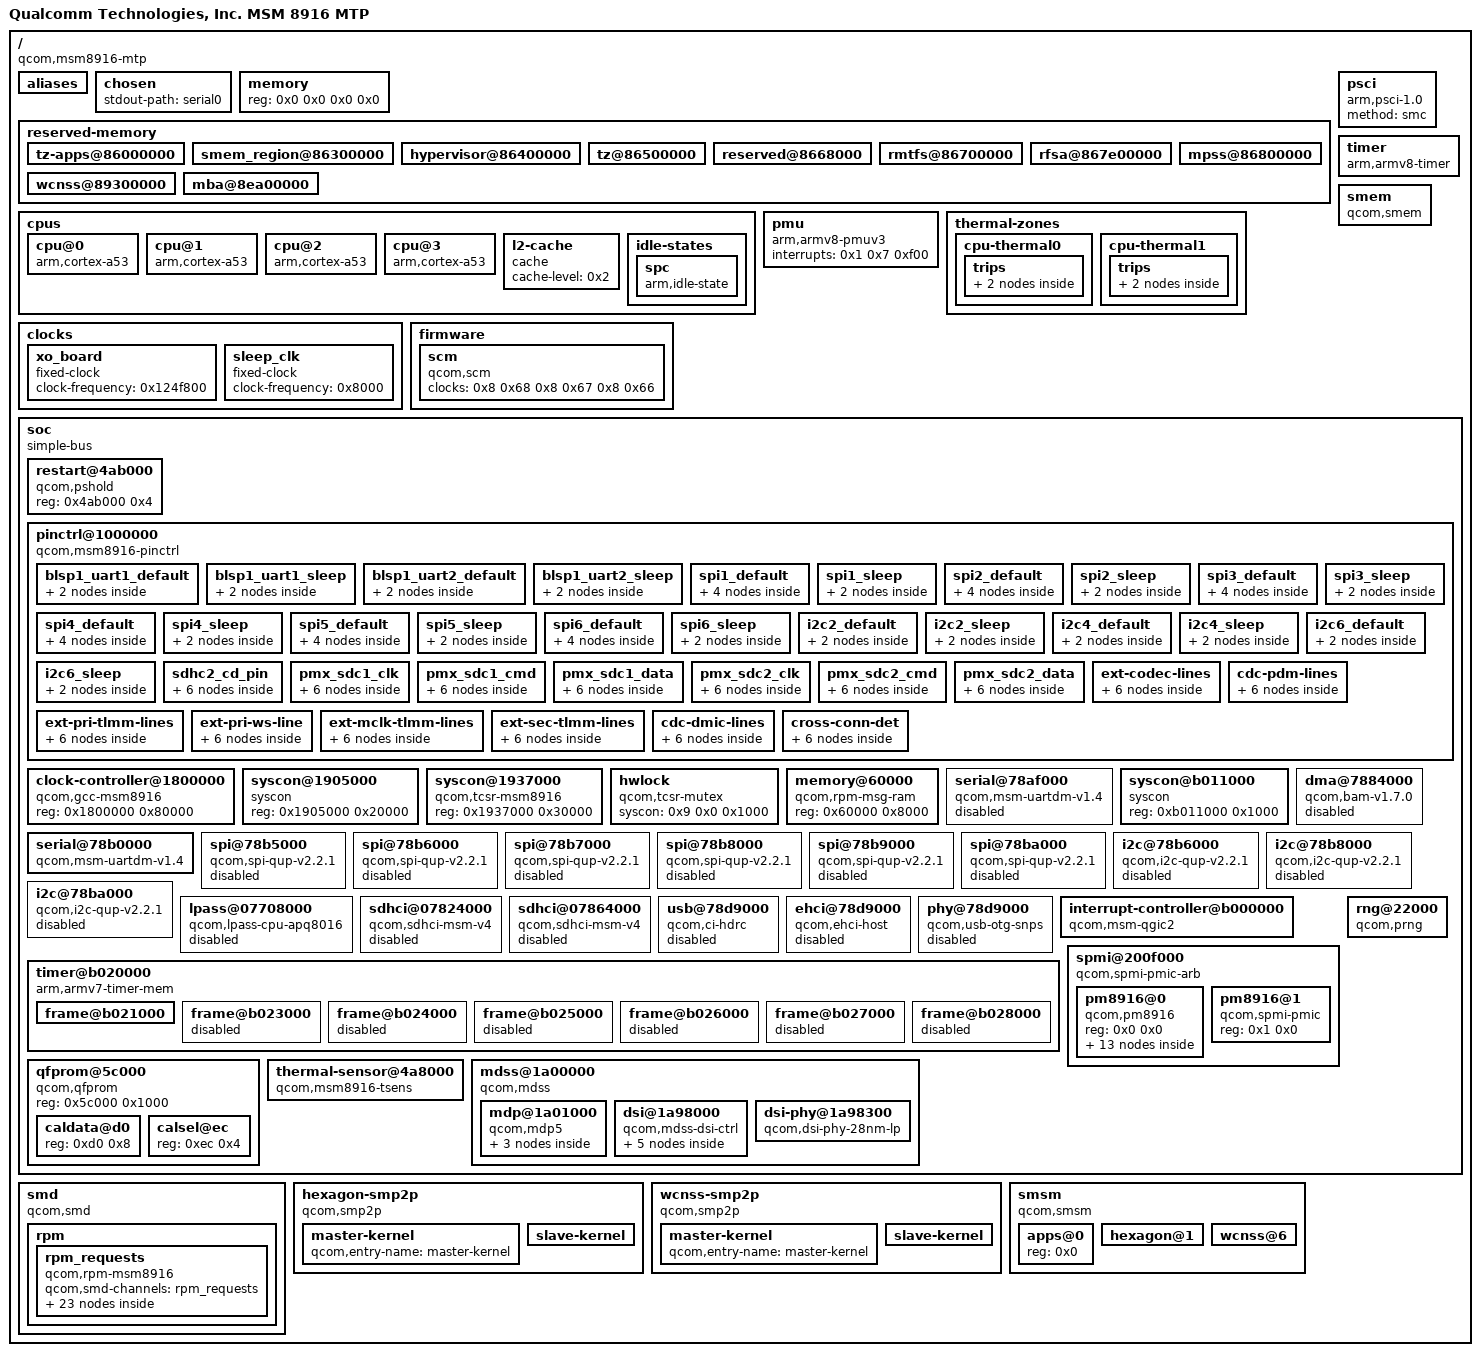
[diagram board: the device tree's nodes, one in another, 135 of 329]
/dts-v1/;

/ {
	model = "Qualcomm Technologies, Inc. MSM 8916 MTP";
	compatible = "qcom,msm8916-mtp", "qcom,msm8916-mtp/1", "qcom,msm8916", "qcom,mtp";
	interrupt-parent = <0x1>;
	#address-cells = <0x2>;
	#size-cells = <0x2>;

	aliases {
		sdhc1 = "/soc/sdhci@07824000";
		sdhc2 = "/soc/sdhci@07864000";
		serial0 = "/soc/serial@78b0000";
		usid0 = "/soc/spmi@200f000/pm8916@0";
	};

	chosen {
		stdout-path = "serial0";
	};

	memory {
		device_type = "memory";
		reg = <0x0 0x0 0x0 0x0>;
	};

	reserved-memory {
		#address-cells = <0x2>;
		#size-cells = <0x2>;
		ranges;

		tz-apps@86000000 {
			reg = <0x0 0x86000000 0x0 0x300000>;
			no-map;
		};

		smem_region@86300000 {
			reg = <0x0 0x86300000 0x0 0x100000>;
			no-map;
			linux,phandle = <0x5>;
			phandle = <0x5>;
		};

		hypervisor@86400000 {
			reg = <0x0 0x86400000 0x0 0x100000>;
			no-map;
		};

		tz@86500000 {
			reg = <0x0 0x86500000 0x0 0x180000>;
			no-map;
		};

		reserved@8668000 {
			reg = <0x0 0x86680000 0x0 0x80000>;
			no-map;
		};

		rmtfs@86700000 {
			reg = <0x0 0x86700000 0x0 0xe0000>;
			no-map;
		};

		rfsa@867e00000 {
			reg = <0x0 0x867e0000 0x0 0x20000>;
			no-map;
		};

		mpss@86800000 {
			reg = <0x0 0x86800000 0x0 0x2b00000>;
			no-map;
		};

		wcnss@89300000 {
			reg = <0x0 0x89300000 0x0 0x600000>;
			no-map;
		};

		mba@8ea00000 {
			no-map;
			reg = <0x0 0x8ea00000 0x0 0x100000>;
			linux,phandle = <0x28>;
			phandle = <0x28>;
		};
	};

	cpus {
		#address-cells = <0x1>;
		#size-cells = <0x0>;

		cpu@0 {
			device_type = "cpu";
			compatible = "arm,cortex-a53", "arm,armv8";
			reg = <0x0>;
			next-level-cache = <0x2>;
			enable-method = "psci";
			cpu-idle-states = <0x3>;
			linux,phandle = <0x29>;
			phandle = <0x29>;
		};

		cpu@1 {
			device_type = "cpu";
			compatible = "arm,cortex-a53", "arm,armv8";
			reg = <0x1>;
			next-level-cache = <0x2>;
			enable-method = "psci";
			cpu-idle-states = <0x3>;
			linux,phandle = <0x2a>;
			phandle = <0x2a>;
		};

		cpu@2 {
			device_type = "cpu";
			compatible = "arm,cortex-a53", "arm,armv8";
			reg = <0x2>;
			next-level-cache = <0x2>;
			enable-method = "psci";
			cpu-idle-states = <0x3>;
			linux,phandle = <0x2b>;
			phandle = <0x2b>;
		};

		cpu@3 {
			device_type = "cpu";
			compatible = "arm,cortex-a53", "arm,armv8";
			reg = <0x3>;
			next-level-cache = <0x2>;
			enable-method = "psci";
			cpu-idle-states = <0x3>;
			linux,phandle = <0x2c>;
			phandle = <0x2c>;
		};

		l2-cache {
			compatible = "cache";
			cache-level = <0x2>;
			linux,phandle = <0x2>;
			phandle = <0x2>;
		};

		idle-states {

			spc {
				compatible = "arm,idle-state";
				arm,psci-suspend-param = <0x40000002>;
				entry-latency-us = <0x82>;
				exit-latency-us = <0x96>;
				min-residency-us = <0x7d0>;
				local-timer-stop;
				linux,phandle = <0x3>;
				phandle = <0x3>;
			};
		};
	};

	psci {
		compatible = "arm,psci-1.0";
		method = "smc";
	};

	pmu {
		compatible = "arm,armv8-pmuv3";
		interrupts = <0x1 0x7 0xf00>;
	};

	thermal-zones {

		cpu-thermal0 {
			polling-delay-passive = <0xfa>;
			polling-delay = <0x3e8>;
			thermal-sensors = <0x4 0x4>;

			trips {

				trip0 {
					temperature = <0x124f8>;
					hysteresis = <0x7d0>;
					type = "passive";
					linux,phandle = <0x2d>;
					phandle = <0x2d>;
				};

				trip1 {
					temperature = <0x1adb0>;
					hysteresis = <0x7d0>;
					type = "critical";
					linux,phandle = <0x2e>;
					phandle = <0x2e>;
				};
			};
		};

		cpu-thermal1 {
			polling-delay-passive = <0xfa>;
			polling-delay = <0x3e8>;
			thermal-sensors = <0x4 0x3>;

			trips {

				trip0 {
					temperature = <0x124f8>;
					hysteresis = <0x7d0>;
					type = "passive";
					linux,phandle = <0x2f>;
					phandle = <0x2f>;
				};

				trip1 {
					temperature = <0x1adb0>;
					hysteresis = <0x7d0>;
					type = "critical";
					linux,phandle = <0x30>;
					phandle = <0x30>;
				};
			};
		};
	};

	timer {
		compatible = "arm,armv8-timer";
		interrupts = <0x1 0x2 0xf08 0x1 0x3 0xf08 0x1 0x4 0xf08 0x1 0x1 0xf08>;
	};

	clocks {

		xo_board {
			compatible = "fixed-clock";
			#clock-cells = <0x0>;
			clock-frequency = <0x124f800>;
			linux,phandle = <0x31>;
			phandle = <0x31>;
		};

		sleep_clk {
			compatible = "fixed-clock";
			#clock-cells = <0x0>;
			clock-frequency = <0x8000>;
			linux,phandle = <0x32>;
			phandle = <0x32>;
		};
	};

	smem {
		compatible = "qcom,smem";
		memory-region = <0x5>;
		qcom,rpm-msg-ram = <0x6>;
		hwlocks = <0x7 0x3>;
	};

	firmware {

		scm {
			compatible = "qcom,scm";
			clocks = <0x8 0x68 0x8 0x67 0x8 0x66>;
			clock-names = "core", "bus", "iface";
			#reset-cells = <0x1>;
			linux,phandle = <0x33>;
			phandle = <0x33>;
		};
	};

	soc {
		#address-cells = <0x1>;
		#size-cells = <0x1>;
		ranges = <0x0 0x0 0x0 0xffffffff>;
		compatible = "simple-bus";
		linux,phandle = <0x34>;
		phandle = <0x34>;

		restart@4ab000 {
			compatible = "qcom,pshold";
			reg = <0x4ab000 0x4>;
		};

		pinctrl@1000000 {
			compatible = "qcom,msm8916-pinctrl";
			reg = <0x1000000 0x300000>;
			interrupts = <0x0 0xd0 0x4>;
			gpio-controller;
			#gpio-cells = <0x2>;
			interrupt-controller;
			#interrupt-cells = <0x2>;
			linux,phandle = <0x35>;
			phandle = <0x35>;

			blsp1_uart1_default {
				linux,phandle = <0x36>;
				phandle = <0x36>;

				pinmux {
					function = "blsp_uart1";
					pins = "gpio0", "gpio1", "gpio2", "gpio3";
				};

				pinconf {
					pins = "gpio0", "gpio1", "gpio2", "gpio3";
					drive-strength = <0x10>;
					bias-disable;
				};
			};

			blsp1_uart1_sleep {
				linux,phandle = <0x37>;
				phandle = <0x37>;

				pinmux {
					function = "gpio";
					pins = "gpio0", "gpio1", "gpio2", "gpio3";
				};

				pinconf {
					pins = "gpio0", "gpio1", "gpio2", "gpio3";
					drive-strength = <0x2>;
					bias-pull-down;
				};
			};

			blsp1_uart2_default {
				linux,phandle = <0xb>;
				phandle = <0xb>;

				pinmux {
					function = "blsp_uart2";
					pins = "gpio4", "gpio5";
				};

				pinconf {
					pins = "gpio4", "gpio5";
					drive-strength = <0x10>;
					bias-disable;
				};
			};

			blsp1_uart2_sleep {
				linux,phandle = <0xc>;
				phandle = <0xc>;

				pinmux {
					function = "gpio";
					pins = "gpio4", "gpio5";
				};

				pinconf {
					pins = "gpio4", "gpio5";
					drive-strength = <0x2>;
					bias-pull-down;
				};
			};

			spi1_default {
				linux,phandle = <0xd>;
				phandle = <0xd>;

				pinmux {
					function = "blsp_spi1";
					pins = "gpio0", "gpio1", "gpio3";
				};

				pinmux_cs {
					function = "gpio";
					pins = "gpio2";
				};

				pinconf {
					pins = "gpio0", "gpio1", "gpio3";
					drive-strength = <0xc>;
					bias-disable;
				};

				pinconf_cs {
					pins = "gpio2";
					drive-strength = <0x10>;
					bias-disable;
					output-high;
				};
			};

			spi1_sleep {
				linux,phandle = <0xe>;
				phandle = <0xe>;

				pinmux {
					function = "gpio";
					pins = "gpio0", "gpio1", "gpio2", "gpio3";
				};

				pinconf {
					pins = "gpio0", "gpio1", "gpio2", "gpio3";
					drive-strength = <0x2>;
					bias-pull-down;
				};
			};

			spi2_default {
				linux,phandle = <0xf>;
				phandle = <0xf>;

				pinmux {
					function = "blsp_spi2";
					pins = "gpio4", "gpio5", "gpio7";
				};

				pinmux_cs {
					function = "gpio";
					pins = "gpio6";
				};

				pinconf {
					pins = "gpio4", "gpio5", "gpio7";
					drive-strength = <0xc>;
					bias-disable;
				};

				pinconf_cs {
					pins = "gpio6";
					drive-strength = <0x10>;
					bias-disable;
					output-high;
				};
			};

			spi2_sleep {
				linux,phandle = <0x10>;
				phandle = <0x10>;

				pinmux {
					function = "gpio";
					pins = "gpio4", "gpio5", "gpio6", "gpio7";
				};

				pinconf {
					pins = "gpio4", "gpio5", "gpio6", "gpio7";
					drive-strength = <0x2>;
					bias-pull-down;
				};
			};

			spi3_default {
				linux,phandle = <0x11>;
				phandle = <0x11>;

				pinmux {
					function = "blsp_spi3";
					pins = "gpio8", "gpio9", "gpio11";
				};

				pinmux_cs {
					function = "gpio";
					pins = "gpio10";
				};

				pinconf {
					pins = "gpio8", "gpio9", "gpio11";
					drive-strength = <0xc>;
					bias-disable;
				};

				pinconf_cs {
					pins = "gpio10";
					drive-strength = <0x10>;
					bias-disable;
					output-high;
				};
			};

			spi3_sleep {
				linux,phandle = <0x12>;
				phandle = <0x12>;

				pinmux {
					function = "gpio";
					pins = "gpio8", "gpio9", "gpio10", "gpio11";
				};

				pinconf {
					pins = "gpio8", "gpio9", "gpio10", "gpio11";
					drive-strength = <0x2>;
					bias-pull-down;
				};
			};

			spi4_default {
				linux,phandle = <0x13>;
				phandle = <0x13>;

				pinmux {
					function = "blsp_spi4";
					pins = "gpio12", "gpio13", "gpio15";
				};

				pinmux_cs {
					function = "gpio";
					pins = "gpio14";
				};

				pinconf {
					pins = "gpio12", "gpio13", "gpio15";
					drive-strength = <0xc>;
					bias-disable;
				};

				pinconf_cs {
					pins = "gpio14";
					drive-strength = <0x10>;
					bias-disable;
					output-high;
				};
			};

			spi4_sleep {
				linux,phandle = <0x14>;
				phandle = <0x14>;

				pinmux {
					function = "gpio";
					pins = "gpio12", "gpio13", "gpio14", "gpio15";
				};

				pinconf {
					pins = "gpio12", "gpio13", "gpio14", "gpio15";
					drive-strength = <0x2>;
					bias-pull-down;
				};
			};

			spi5_default {
				linux,phandle = <0x15>;
				phandle = <0x15>;

				pinmux {
					function = "blsp_spi5";
					pins = "gpio16", "gpio17", "gpio19";
				};

				pinmux_cs {
					function = "gpio";
					pins = "gpio18";
				};

				pinconf {
					pins = "gpio16", "gpio17", "gpio19";
					drive-strength = <0xc>;
					bias-disable;
				};

				pinconf_cs {
					pins = "gpio18";
					drive-strength = <0x10>;
					bias-disable;
					output-high;
				};
			};

			spi5_sleep {
				linux,phandle = <0x16>;
				phandle = <0x16>;

				pinmux {
					function = "gpio";
					pins = "gpio16", "gpio17", "gpio18", "gpio19";
				};

				pinconf {
					pins = "gpio16", "gpio17", "gpio18", "gpio19";
					drive-strength = <0x2>;
					bias-pull-down;
				};
			};

			spi6_default {
				linux,phandle = <0x17>;
				phandle = <0x17>;

				pinmux {
					function = "blsp_spi6";
					pins = "gpio20", "gpio21", "gpio23";
				};

				pinmux_cs {
					function = "gpio";
					pins = "gpio22";
				};

				pinconf {
					pins = "gpio20", "gpio21", "gpio23";
					drive-strength = <0xc>;
					bias-disable;
				};

				pinconf_cs {
					pins = "gpio22";
					drive-strength = <0x10>;
					bias-disable;
					output-high;
				};
			};

			spi6_sleep {
				linux,phandle = <0x18>;
				phandle = <0x18>;

				pinmux {
					function = "gpio";
					pins = "gpio20", "gpio21", "gpio22", "gpio23";
				};

				pinconf {
					pins = "gpio20", "gpio21", "gpio22", "gpio23";
					drive-strength = <0x2>;
					bias-pull-down;
				};
			};

			i2c2_default {
				linux,phandle = <0x19>;
				phandle = <0x19>;

				pinmux {
					function = "blsp_i2c2";
					pins = "gpio6", "gpio7";
				};

				pinconf {
					pins = "gpio6", "gpio7";
					drive-strength = <0x10>;
					bias-disable = <0x0>;
				};
			};

			i2c2_sleep {
				linux,phandle = <0x1a>;
				phandle = <0x1a>;

				pinmux {
					function = "gpio";
					pins = "gpio6", "gpio7";
				};

				pinconf {
					pins = "gpio6", "gpio7";
					drive-strength = <0x2>;
					bias-disable = <0x0>;
				};
			};

			i2c4_default {
				linux,phandle = <0x1b>;
				phandle = <0x1b>;

				pinmux {
					function = "blsp_i2c4";
					pins = "gpio14", "gpio15";
				};

				pinconf {
					pins = "gpio14", "gpio15";
					drive-strength = <0x10>;
					bias-disable = <0x0>;
				};
			};

			i2c4_sleep {
				linux,phandle = <0x1c>;
				phandle = <0x1c>;

				pinmux {
					function = "gpio";
					pins = "gpio14", "gpio15";
				};

				pinconf {
					pins = "gpio14", "gpio15";
					drive-strength = <0x2>;
					bias-disable = <0x0>;
				};
			};

			i2c6_default {
				linux,phandle = <0x1d>;
				phandle = <0x1d>;

				pinmux {
					function = "blsp_i2c6";
					pins = "gpio22", "gpio23";
				};

				pinconf {
					pins = "gpio22", "gpio23";
					drive-strength = <0x10>;
					bias-disable = <0x0>;
				};
			};

			i2c6_sleep {
				linux,phandle = <0x1e>;
				phandle = <0x1e>;

				pinmux {
					function = "gpio";
					pins = "gpio22", "gpio23";
				};

				pinconf {
					pins = "gpio22", "gpio23";
					drive-strength = <0x2>;
					bias-disable = <0x0>;
				};
			};

			sdhc2_cd_pin {

				cd_on {
					linux,phandle = <0x38>;
					phandle = <0x38>;

					pinmux {
						function = "gpio";
						pins = "gpio38";
					};

					pinconf {
						pins = "gpio38";
						drive-strength = <0x2>;
						bias-pull-up;
					};
				};

				cd_off {
					linux,phandle = <0x39>;
					phandle = <0x39>;

					pinmux {
						function = "gpio";
						pins = "gpio38";
					};

					pinconf {
						pins = "gpio38";
						drive-strength = <0x2>;
						bias-disable;
					};
				};
			};

			pmx_sdc1_clk {

				clk_on {
					linux,phandle = <0x3a>;
					phandle = <0x3a>;

					pinmux {
						pins = "sdc1_clk";
					};

					pinconf {
						pins = "sdc1_clk";
						bias-disable;
						drive-strength = <0x10>;
					};
				};

				clk_off {
					linux,phandle = <0x3b>;
					phandle = <0x3b>;

					pinmux {
						pins = "sdc1_clk";
					};

					pinconf {
						pins = "sdc1_clk";
						bias-disable;
						drive-strength = <0x2>;
					};
				};
			};

			pmx_sdc1_cmd {

				cmd_on {
					linux,phandle = <0x3c>;
					phandle = <0x3c>;

					pinmux {
						pins = "sdc1_cmd";
					};

					pinconf {
						pins = "sdc1_cmd";
						bias-pull-up;
						drive-strength = <0xa>;
					};
				};

				cmd_off {
					linux,phandle = <0x3d>;
					phandle = <0x3d>;

					pinmux {
						pins = "sdc1_cmd";
					};

					pinconf {
						pins = "sdc1_cmd";
						bias-pull-up;
						drive-strength = <0x2>;
					};
				};
			};

			pmx_sdc1_data {

				data_on {
					linux,phandle = <0x3e>;
					phandle = <0x3e>;

					pinmux {
						pins = "sdc1_data";
					};

					pinconf {
						pins = "sdc1_data";
						bias-pull-up;
						drive-strength = <0xa>;
					};
				};

				data_off {
					linux,phandle = <0x3f>;
					phandle = <0x3f>;

					pinmux {
						pins = "sdc1_data";
					};

					pinconf {
						pins = "sdc1_data";
						bias-pull-up;
						drive-strength = <0x2>;
					};
				};
			};

			pmx_sdc2_clk {

				clk_on {
					linux,phandle = <0x40>;
					phandle = <0x40>;

					pinmux {
						pins = "sdc2_clk";
					};

					pinconf {
						pins = "sdc2_clk";
						bias-disable;
						drive-strength = <0x10>;
					};
				};

				clk_off {
					linux,phandle = <0x41>;
					phandle = <0x41>;

					pinmux {
						pins = "sdc2_clk";
					};

					pinconf {
						pins = "sdc2_clk";
						bias-disable;
						drive-strength = <0x2>;
					};
				};
			};

			pmx_sdc2_cmd {

				cmd_on {
					linux,phandle = <0x42>;
					phandle = <0x42>;

					pinmux {
						pins = "sdc2_cmd";
					};

					pinconf {
						pins = "sdc2_cmd";
						bias-pull-up;
						drive-strength = <0xa>;
					};
				};

				cmd_off {
					linux,phandle = <0x43>;
					phandle = <0x43>;

					pinmux {
						pins = "sdc2_cmd";
					};

					pinconf {
						pins = "sdc2_cmd";
						bias-pull-up;
						drive-strength = <0x2>;
					};
				};
			};

			pmx_sdc2_data {

				data_on {
					linux,phandle = <0x44>;
					phandle = <0x44>;

					pinmux {
						pins = "sdc2_data";
					};

					pinconf {
						pins = "sdc2_data";
						bias-pull-up;
						drive-strength = <0xa>;
					};
				};

				data_off {
					linux,phandle = <0x45>;
					phandle = <0x45>;

					pinmux {
						pins = "sdc2_data";
					};

					pinconf {
						pins = "sdc2_data";
						bias-pull-up;
						drive-strength = <0x2>;
					};
				};
			};

			ext-codec-lines {

				lines_on {
					linux,phandle = <0x46>;
					phandle = <0x46>;

					pinmux {
						function = "gpio";
						pins = "gpio67";
					};

					pinconf {
						pins = "gpio67";
						drive-strength = <0x8>;
						bias-disable;
						output-high;
					};
				};

				lines_off {
					linux,phandle = <0x47>;
					phandle = <0x47>;

					pinmux {
						function = "gpio";
						pins = "gpio67";
					};

					pinconf {
						pins = "gpio67";
						drive-strength = <0x2>;
						bias-disable;
					};
				};
			};

			cdc-pdm-lines {

				pdm_lines_on {
					linux,phandle = <0x48>;
					phandle = <0x48>;

					pinmux {
						function = "cdc_pdm0";
						pins = "gpio63", "gpio64", "gpio65", "gpio66", "gpio67", "gpio68";
					};

					pinconf {
						pins = "gpio63", "gpio64", "gpio65", "gpio66", "gpio67", "gpio68";
						drive-strength = <0x8>;
						bias-pull-none;
					};
				};

				pdm_lines_off {
					linux,phandle = <0x49>;
					phandle = <0x49>;

					pinmux {
						function = "cdc_pdm0";
						pins = "gpio63", "gpio64", "gpio65", "gpio66", "gpio67", "gpio68";
					};

					pinconf {
						pins = "gpio63", "gpio64", "gpio65", "gpio66", "gpio67", "gpio68";
						drive-strength = <0x2>;
						bias-disable;
					};
				};
			};

			ext-pri-tlmm-lines {

				ext_pa_on {
					linux,phandle = <0x4a>;
					phandle = <0x4a>;

					pinmux {
						function = "pri_mi2s";
						pins = "gpio113", "gpio114", "gpio115", "gpio116";
					};

					pinconf {
						pins = "gpio113", "gpio114", "gpio115", "gpio116";
						drive-strength = <0x8>;
						bias-pull-none;
					};
				};

				ext_pa_off {
					linux,phandle = <0x4b>;
					phandle = <0x4b>;

					pinmux {
						function = "pri_mi2s";
						pins = "gpio113", "gpio114", "gpio115", "gpio116";
					};

					pinconf {
						pins = "gpio113", "gpio114", "gpio115", "gpio116";
						drive-strength = <0x2>;
						bias-disable;
					};
				};
			};

			ext-pri-ws-line {

				ext_pa_on {
					linux,phandle = <0x4c>;
					phandle = <0x4c>;

					pinmux {
						function = "pri_mi2s_ws";
						pins = "gpio110";
					};

					pinconf {
						pins = "gpio110";
						drive-strength = <0x8>;
						bias-pull-none;
					};
				};

				ext_pa_off {
					linux,phandle = <0x4d>;
					phandle = <0x4d>;

					pinmux {
						function = "pri_mi2s_ws";
						pins = "gpio110";
					};

					pinconf {
						pins = "gpio110";
						drive-strength = <0x2>;
						bias-disable;
					};
				};
			};

			ext-mclk-tlmm-lines {

				mclk_lines_on {
					linux,phandle = <0x4e>;
					phandle = <0x4e>;

					pinmux {
						function = "pri_mi2s";
						pins = "gpio116";
					};

					pinconf {
						pins = "gpio116";
						drive-strength = <0x8>;
						bias-pull-none;
					};
				};

				mclk_lines_off {
					linux,phandle = <0x4f>;
					phandle = <0x4f>;

					pinmux {
						function = "pri_mi2s";
						pins = "gpio116";
					};

					pinconf {
						pins = "gpio116";
						drive-strength = <0x2>;
						bias-disable;
					};
				};
			};

			ext-sec-tlmm-lines {

				tlmm_lines_on {
					linux,phandle = <0x50>;
					phandle = <0x50>;

					pinmux {
						function = "sec_mi2s";
						pins = "gpio112", "gpio117", "gpio118", "gpio119";
					};

					pinconf {
						pins = "gpio112", "gpio117", "gpio118", "gpio119";
						drive-strength = <0x8>;
						bias-pull-none;
					};
				};

				tlmm_lines_off {
					linux,phandle = <0x51>;
					phandle = <0x51>;

					pinmux {
						function = "sec_mi2s";
						pins = "gpio112", "gpio117", "gpio118", "gpio119";
					};

					pinconf {
						pins = "gpio112", "gpio117", "gpio118", "gpio119";
						drive-strength = <0x2>;
						bias-disable;
					};
				};
			};

			cdc-dmic-lines {

				dmic_lines_on {
					linux,phandle = <0x52>;
					phandle = <0x52>;

					pinmux_dmic0_clk {
						function = "dmic0_clk";
						pins = "gpio0";
					};

					pinmux_dmic0_data {
						function = "dmic0_data";
						pins = "gpio1";
					};

					pinconf {
						pins = "gpio0", "gpio1";
						drive-strength = <0x8>;
					};
				};

				dmic_lines_off {
					linux,phandle = <0x53>;
					phandle = <0x53>;

					pinconf {
						pins = "gpio0", "gpio1";
						drive-strength = <0x2>;
						bias-disable;
					};
				};
			};

			cross-conn-det {

				lines_on {
					linux,phandle = <0x54>;
					phandle = <0x54>;

					pinmux {
						function = "gpio";
						pins = "gpio120";
					};

					pinconf {
						pins = "gpio120";
						drive-strength = <0x8>;
						output-low;
						bias-pull-down;
					};
				};

				lines_off {
					linux,phandle = <0x55>;
					phandle = <0x55>;

					pinmux {
						function = "gpio";
						pins = "gpio120";
					};

					pinconf {
						pins = "gpio120";
						drive-strength = <0x2>;
						bias-disable;
					};
				};
			};
		};

		clock-controller@1800000 {
			compatible = "qcom,gcc-msm8916";
			#clock-cells = <0x1>;
			#reset-cells = <0x1>;
			#power-domain-cells = <0x1>;
			reg = <0x1800000 0x80000>;
			linux,phandle = <0x8>;
			phandle = <0x8>;
		};

		syscon@1905000 {
			compatible = "syscon";
			reg = <0x1905000 0x20000>;
			linux,phandle = <0x9>;
			phandle = <0x9>;
		};

		syscon@1937000 {
			compatible = "qcom,tcsr-msm8916", "syscon";
			reg = <0x1937000 0x30000>;
			linux,phandle = <0x56>;
			phandle = <0x56>;
		};

		hwlock {
			compatible = "qcom,tcsr-mutex";
			syscon = <0x9 0x0 0x1000>;
			#hwlock-cells = <0x1>;
			linux,phandle = <0x7>;
			phandle = <0x7>;
		};

		memory@60000 {
			compatible = "qcom,rpm-msg-ram";
			reg = <0x60000 0x8000>;
			linux,phandle = <0x6>;
			phandle = <0x6>;
		};

		serial@78af000 {
			compatible = "qcom,msm-uartdm-v1.4", "qcom,msm-uartdm";
			reg = <0x78af000 0x200>;
			interrupts = <0x0 0x6b 0x4>;
			clocks = <0x8 0x44 0x8 0x36>;
			clock-names = "core", "iface";
			dmas = <0xa 0x1 0xa 0x0>;
			dma-names = "rx", "tx";
			status = "disabled";
			linux,phandle = <0x57>;
			phandle = <0x57>;
		};

		syscon@b011000 {
			compatible = "syscon";
			reg = <0xb011000 0x1000>;
			linux,phandle = <0x27>;
			phandle = <0x27>;
		};

		serial@78b0000 {
			compatible = "qcom,msm-uartdm-v1.4", "qcom,msm-uartdm";
			reg = <0x78b0000 0x200>;
			interrupts = <0x0 0x6c 0x4>;
			clocks = <0x8 0x45 0x8 0x36>;
			clock-names = "core", "iface";
			dmas = <0xa 0x3 0xa 0x2>;
			dma-names = "rx", "tx";
			status = "okay";
			pinctrl-names = "default", "sleep";
			pinctrl-0 = <0xb>;
			pinctrl-1 = <0xc>;
			linux,phandle = <0x58>;
			phandle = <0x58>;
		};

		dma@7884000 {
			compatible = "qcom,bam-v1.7.0";
			reg = <0x7884000 0x23000>;
			interrupts = <0x0 0xee 0x4>;
			clocks = <0x8 0x36>;
			clock-names = "bam_clk";
			#dma-cells = <0x1>;
			qcom,ee = <0x0>;
			status = "disabled";
			linux,phandle = <0xa>;
			phandle = <0xa>;
		};

		spi@78b5000 {
			compatible = "qcom,spi-qup-v2.2.1";
			reg = <0x78b5000 0x600>;
			interrupts = <0x0 0x5f 0x4>;
			clocks = <0x8 0x39 0x8 0x36>;
			clock-names = "core", "iface";
			dmas = <0xa 0x5 0xa 0x4>;
			dma-names = "rx", "tx";
			pinctrl-names = "default", "sleep";
			pinctrl-0 = <0xd>;
			pinctrl-1 = <0xe>;
			#address-cells = <0x1>;
			#size-cells = <0x0>;
			status = "disabled";
			linux,phandle = <0x59>;
			phandle = <0x59>;
		};

		spi@78b6000 {
			compatible = "qcom,spi-qup-v2.2.1";
			reg = <0x78b6000 0x600>;
			interrupts = <0x0 0x60 0x4>;
			clocks = <0x8 0x3b 0x8 0x36>;
			clock-names = "core", "iface";
			dmas = <0xa 0x7 0xa 0x6>;
			dma-names = "rx", "tx";
			pinctrl-names = "default", "sleep";
			pinctrl-0 = <0xf>;
			pinctrl-1 = <0x10>;
			#address-cells = <0x1>;
			#size-cells = <0x0>;
			status = "disabled";
			linux,phandle = <0x5a>;
			phandle = <0x5a>;
		};

		spi@78b7000 {
			compatible = "qcom,spi-qup-v2.2.1";
			reg = <0x78b7000 0x600>;
			interrupts = <0x0 0x61 0x4>;
			clocks = <0x8 0x3d 0x8 0x36>;
			clock-names = "core", "iface";
			dmas = <0xa 0x9 0xa 0x8>;
			dma-names = "rx", "tx";
			pinctrl-names = "default", "sleep";
			pinctrl-0 = <0x11>;
			pinctrl-1 = <0x12>;
			#address-cells = <0x1>;
			#size-cells = <0x0>;
			status = "disabled";
			linux,phandle = <0x5b>;
			phandle = <0x5b>;
		};

		spi@78b8000 {
			compatible = "qcom,spi-qup-v2.2.1";
			reg = <0x78b8000 0x600>;
			interrupts = <0x0 0x62 0x4>;
			clocks = <0x8 0x3f 0x8 0x36>;
			clock-names = "core", "iface";
			dmas = <0xa 0xb 0xa 0xa>;
			dma-names = "rx", "tx";
			pinctrl-names = "default", "sleep";
			pinctrl-0 = <0x13>;
			pinctrl-1 = <0x14>;
			#address-cells = <0x1>;
			#size-cells = <0x0>;
			status = "disabled";
			linux,phandle = <0x5c>;
			phandle = <0x5c>;
		};

		spi@78b9000 {
			compatible = "qcom,spi-qup-v2.2.1";
			reg = <0x78b9000 0x600>;
			interrupts = <0x0 0x63 0x4>;
			clocks = <0x8 0x41 0x8 0x36>;
			clock-names = "core", "iface";
			dmas = <0xa 0xd 0xa 0xc>;
			dma-names = "rx", "tx";
			pinctrl-names = "default", "sleep";
			pinctrl-0 = <0x15>;
			pinctrl-1 = <0x16>;
			#address-cells = <0x1>;
			#size-cells = <0x0>;
			status = "disabled";
			linux,phandle = <0x5d>;
			phandle = <0x5d>;
		};

		spi@78ba000 {
			compatible = "qcom,spi-qup-v2.2.1";
			reg = <0x78ba000 0x600>;
			interrupts = <0x0 0x64 0x4>;
			clocks = <0x8 0x43 0x8 0x36>;
			clock-names = "core", "iface";
			dmas = <0xa 0xf 0xa 0xe>;
			dma-names = "rx", "tx";
			pinctrl-names = "default", "sleep";
			pinctrl-0 = <0x17>;
			pinctrl-1 = <0x18>;
			#address-cells = <0x1>;
			#size-cells = <0x0>;
			status = "disabled";
			linux,phandle = <0x5e>;
			phandle = <0x5e>;
		};

		i2c@78b6000 {
			compatible = "qcom,i2c-qup-v2.2.1";
			reg = <0x78b6000 0x1000>;
			interrupts = <0x0 0x60 0x0>;
			clocks = <0x8 0x36 0x8 0x3a>;
			clock-names = "iface", "core";
			pinctrl-names = "default", "sleep";
			pinctrl-0 = <0x19>;
			pinctrl-1 = <0x1a>;
			#address-cells = <0x1>;
			#size-cells = <0x0>;
			status = "disabled";
			linux,phandle = <0x5f>;
			phandle = <0x5f>;
		};

		i2c@78b8000 {
			compatible = "qcom,i2c-qup-v2.2.1";
			reg = <0x78b8000 0x1000>;
			interrupts = <0x0 0x62 0x0>;
			clocks = <0x8 0x36 0x8 0x3e>;
			clock-names = "iface", "core";
			pinctrl-names = "default", "sleep";
			pinctrl-0 = <0x1b>;
			pinctrl-1 = <0x1c>;
			#address-cells = <0x1>;
			#size-cells = <0x0>;
			status = "disabled";
			linux,phandle = <0x60>;
			phandle = <0x60>;
		};

		i2c@78ba000 {
			compatible = "qcom,i2c-qup-v2.2.1";
			reg = <0x78ba000 0x1000>;
			interrupts = <0x0 0x64 0x0>;
			clocks = <0x8 0x36 0x8 0x42>;
			clock-names = "iface", "core";
			pinctrl-names = "default", "sleep";
			pinctrl-0 = <0x1d>;
			pinctrl-1 = <0x1e>;
			#address-cells = <0x1>;
			#size-cells = <0x0>;
			status = "disabled";
			linux,phandle = <0x61>;
			phandle = <0x61>;
		};

		lpass@07708000 {
			status = "disabled";
			compatible = "qcom,lpass-cpu-apq8016";
			clocks = <0x8 0x9a 0x8 0x96 0x8 0x97 0x8 0x9c 0x8 0x9d 0x8 0x9d 0x8 0x9e>;
			clock-names = "ahbix-clk", "pcnoc-mport-clk", "pcnoc-sway-clk", "mi2s-bit-clk0", "mi2s-bit-clk1", "mi2s-bit-clk2", "mi2s-bit-clk3";
			#sound-dai-cells = <0x1>;
			interrupts = <0x0 0xa0 0x0>;
			interrupt-names = "lpass-irq-lpaif";
			reg = <0x7708000 0x10000>;
			reg-names = "lpass-lpaif";
			linux,phandle = <0x62>;
			phandle = <0x62>;
		};

		sdhci@07824000 {
			compatible = "qcom,sdhci-msm-v4";
			reg = <0x7824900 0x11c 0x7824000 0x800>;
			reg-names = "hc_mem", "core_mem";
			interrupts = <0x0 0x7b 0x0 0x0 0x8a 0x0>;
			interrupt-names = "hc_irq", "pwr_irq";
			clocks = <0x8 0x7b 0x8 0x7a>;
			clock-names = "core", "iface";
			bus-width = <0x8>;
			non-removable;
			status = "disabled";
			linux,phandle = <0x63>;
			phandle = <0x63>;
		};

		sdhci@07864000 {
			compatible = "qcom,sdhci-msm-v4";
			reg = <0x7864900 0x11c 0x7864000 0x800>;
			reg-names = "hc_mem", "core_mem";
			interrupts = <0x0 0x7d 0x0 0x0 0xdd 0x0>;
			interrupt-names = "hc_irq", "pwr_irq";
			clocks = <0x8 0x7d 0x8 0x7c>;
			clock-names = "core", "iface";
			bus-width = <0x4>;
			status = "disabled";
			linux,phandle = <0x64>;
			phandle = <0x64>;
		};

		usb@78d9000 {
			compatible = "qcom,ci-hdrc";
			reg = <0x78d9000 0x400>;
			dr_mode = "peripheral";
			interrupts = <0x0 0x86 0x4>;
			usb-phy = <0x1f>;
			status = "disabled";
			linux,phandle = <0x65>;
			phandle = <0x65>;
		};

		ehci@78d9000 {
			compatible = "qcom,ehci-host";
			reg = <0x78d9000 0x400>;
			interrupts = <0x0 0x86 0x4>;
			usb-phy = <0x1f>;
			status = "disabled";
			linux,phandle = <0x66>;
			phandle = <0x66>;
		};

		phy@78d9000 {
			compatible = "qcom,usb-otg-snps";
			reg = <0x78d9000 0x400>;
			interrupts = <0x0 0x86 0x4 0x0 0x8c 0x4>;
			qcom,vdd-levels = <0x7a120 0xf4240 0x142440>;
			qcom,phy-init-sequence = <0x44 0x6b 0x24 0x13>;
			dr_mode = "peripheral";
			qcom,otg-control = <0x2>;
			qcom,manual-pullup;
			clocks = <0x8 0x85 0x8 0x86 0x8 0x84>;
			clock-names = "iface", "core", "sleep";
			resets = <0x8 0x23 0x8 0x22>;
			reset-names = "phy", "link";
			status = "disabled";
			linux,phandle = <0x1f>;
			phandle = <0x1f>;
		};

		interrupt-controller@b000000 {
			compatible = "qcom,msm-qgic2";
			interrupt-controller;
			#interrupt-cells = <0x3>;
			reg = <0xb000000 0x1000 0xb002000 0x1000>;
			linux,phandle = <0x1>;
			phandle = <0x1>;
		};

		timer@b020000 {
			#address-cells = <0x1>;
			#size-cells = <0x1>;
			ranges;
			compatible = "arm,armv7-timer-mem";
			reg = <0xb020000 0x1000>;
			clock-frequency = <0x124f800>;

			frame@b021000 {
				frame-number = <0x0>;
				interrupts = <0x0 0x8 0x4 0x0 0x7 0x4>;
				reg = <0xb021000 0x1000 0xb022000 0x1000>;
			};

			frame@b023000 {
				frame-number = <0x1>;
				interrupts = <0x0 0x9 0x4>;
				reg = <0xb023000 0x1000>;
				status = "disabled";
			};

			frame@b024000 {
				frame-number = <0x2>;
				interrupts = <0x0 0xa 0x4>;
				reg = <0xb024000 0x1000>;
				status = "disabled";
			};

			frame@b025000 {
				frame-number = <0x3>;
				interrupts = <0x0 0xb 0x4>;
				reg = <0xb025000 0x1000>;
				status = "disabled";
			};

			frame@b026000 {
				frame-number = <0x4>;
				interrupts = <0x0 0xc 0x4>;
				reg = <0xb026000 0x1000>;
				status = "disabled";
			};

			frame@b027000 {
				frame-number = <0x5>;
				interrupts = <0x0 0xd 0x4>;
				reg = <0xb027000 0x1000>;
				status = "disabled";
			};

			frame@b028000 {
				frame-number = <0x6>;
				interrupts = <0x0 0xe 0x4>;
				reg = <0xb028000 0x1000>;
				status = "disabled";
			};
		};

		spmi@200f000 {
			compatible = "qcom,spmi-pmic-arb";
			reg = <0x200f000 0x1000 0x2400000 0x400000 0x2c00000 0x400000 0x3800000 0x200000 0x200a000 0x2100>;
			reg-names = "core", "chnls", "obsrvr", "intr", "cnfg";
			interrupt-names = "periph_irq";
			interrupts = <0x0 0xbe 0x4>;
			qcom,ee = <0x0>;
			qcom,channel = <0x0>;
			#address-cells = <0x2>;
			#size-cells = <0x0>;
			interrupt-controller;
			#interrupt-cells = <0x4>;
			linux,phandle = <0x67>;
			phandle = <0x67>;

			pm8916@0 {
				compatible = "qcom,pm8916", "qcom,spmi-pmic";
				reg = <0x0 0x0>;
				#address-cells = <0x1>;
				#size-cells = <0x0>;
				linux,phandle = <0x68>;
				phandle = <0x68>;

				rtc@6000 {
					compatible = "qcom,pm8941-rtc";
					reg = <0x6000>;
					reg-names = "rtc", "alarm";
					interrupts = <0x0 0x61 0x1 0x1>;
				};

				pwrkey@800 {
					compatible = "qcom,pm8941-pwrkey";
					reg = <0x800>;
					interrupts = <0x0 0x8 0x0 0x3>;
					debounce = <0x3d09>;
					bias-pull-up;
				};

				gpios@c000 {
					compatible = "qcom,pm8916-gpio";
					reg = <0xc000>;
					gpio-controller;
					#gpio-cells = <0x2>;
					interrupts = <0x0 0xc0 0x0 0x0 0x0 0xc1 0x0 0x0 0x0 0xc2 0x0 0x0 0x0 0xc3 0x0 0x0>;
					linux,phandle = <0x69>;
					phandle = <0x69>;
				};

				mpps@a000 {
					compatible = "qcom,pm8916-mpp";
					reg = <0xa000>;
					gpio-controller;
					#gpio-cells = <0x2>;
					interrupts = <0x0 0xa0 0x0 0x0 0x0 0xa1 0x0 0x0 0x0 0xa2 0x0 0x0 0x0 0xa3 0x0 0x0>;
					linux,phandle = <0x6a>;
					phandle = <0x6a>;
				};

				temp-alarm@2400 {
					compatible = "qcom,spmi-temp-alarm";
					reg = <0x2400>;
					interrupts = <0x0 0x24 0x0 0x1>;
					io-channels = <0x20 0x8>;
					io-channel-names = "thermal";
					#thermal-sensor-cells = <0x0>;
					linux,phandle = <0x6b>;
					phandle = <0x6b>;
				};

				vadc@3100 {
					compatible = "qcom,spmi-vadc";
					reg = <0x3100>;
					interrupts = <0x0 0x31 0x0 0x1>;
					#address-cells = <0x1>;
					#size-cells = <0x0>;
					#io-channel-cells = <0x1>;
					linux,phandle = <0x20>;
					phandle = <0x20>;

					usb_in {
						reg = <0x0>;
						qcom,pre-scaling = <0x1 0xa>;
					};

					vph_pwr {
						reg = <0x7>;
						qcom,pre-scaling = <0x1 0x3>;
					};

					die_temp {
						reg = <0x8>;
					};

					ref_625mv {
						reg = <0x9>;
					};

					ref_1250v {
						reg = <0xa>;
					};

					ref_gnd {
						reg = <0xe>;
					};

					ref_vdd {
						reg = <0xf>;
					};
				};
			};

			pm8916@1 {
				compatible = "qcom,spmi-pmic";
				reg = <0x1 0x0>;
				#address-cells = <0x1>;
				#size-cells = <0x0>;
				linux,phandle = <0x6c>;
				phandle = <0x6c>;
			};
		};

		rng@22000 {
			compatible = "qcom,prng";
			reg = <0x22000 0x200>;
			clocks = <0x8 0x79>;
			clock-names = "core";
		};

		qfprom@5c000 {
			compatible = "qcom,qfprom";
			reg = <0x5c000 0x1000>;
			#address-cells = <0x1>;
			#size-cells = <0x1>;
			linux,phandle = <0x6d>;
			phandle = <0x6d>;

			caldata@d0 {
				reg = <0xd0 0x8>;
				linux,phandle = <0x21>;
				phandle = <0x21>;
			};

			calsel@ec {
				reg = <0xec 0x4>;
				linux,phandle = <0x22>;
				phandle = <0x22>;
			};
		};

		thermal-sensor@4a8000 {
			compatible = "qcom,msm8916-tsens";
			reg = <0x4a8000 0x2000>;
			nvmem-cells = <0x21 0x22>;
			nvmem-cell-names = "calib", "calib_sel";
			#thermal-sensor-cells = <0x1>;
			linux,phandle = <0x4>;
			phandle = <0x4>;
		};

		mdss@1a00000 {
			compatible = "qcom,mdss";
			reg = <0x1a00000 0x1000 0x1ac8000 0x3000>;
			reg-names = "mdss_phys", "vbif_phys";
			power-domains = <0x8 0x2>;
			clocks = <0x8 0x6d 0x8 0x6e 0x8 0x73>;
			clock-names = "iface_clk", "bus_clk", "vsync_clk";
			interrupts = <0x0 0x48 0x0>;
			interrupt-controller;
			#interrupt-cells = <0x1>;
			#address-cells = <0x1>;
			#size-cells = <0x1>;
			ranges;
			linux,phandle = <0x23>;
			phandle = <0x23>;

			mdp@1a01000 {
				compatible = "qcom,mdp5";
				reg = <0x1a01000 0x90000>;
				reg-names = "mdp_phys";
				interrupt-parent = <0x23>;
				interrupts = <0x0 0x0>;
				clocks = <0x8 0x6d 0x8 0x6e 0x8 0x71 0x8 0x73>;
				clock-names = "iface_clk", "bus_clk", "core_clk", "vsync_clk";
				linux,phandle = <0x6e>;
				phandle = <0x6e>;

				ports {
					#address-cells = <0x1>;
					#size-cells = <0x0>;

					port@0 {
						reg = <0x0>;

						endpoint {
							remote-endpoint = <0x24>;
							linux,phandle = <0x26>;
							phandle = <0x26>;
						};
					};
				};
			};

			dsi@1a98000 {
				compatible = "qcom,mdss-dsi-ctrl";
				reg = <0x1a98000 0x25c>;
				reg-names = "dsi_ctrl";
				interrupt-parent = <0x23>;
				interrupts = <0x4 0x0>;
				assigned-clocks = <0x8 0x2b 0x8 0x2e>;
				assigned-clock-parents = <0x25 0x0 0x25 0x1>;
				clocks = <0x8 0x71 0x8 0x6d 0x8 0x6e 0x8 0x6f 0x8 0x72 0x8 0x70>;
				clock-names = "mdp_core_clk", "iface_clk", "bus_clk", "byte_clk", "pixel_clk", "core_clk";
				phys = <0x25>;
				phy-names = "dsi-phy";
				linux,phandle = <0x6f>;
				phandle = <0x6f>;

				ports {
					#address-cells = <0x1>;
					#size-cells = <0x0>;

					port@0 {
						reg = <0x0>;

						endpoint {
							remote-endpoint = <0x26>;
							linux,phandle = <0x24>;
							phandle = <0x24>;
						};
					};

					port@1 {
						reg = <0x1>;

						endpoint {
							linux,phandle = <0x70>;
							phandle = <0x70>;
						};
					};
				};
			};

			dsi-phy@1a98300 {
				compatible = "qcom,dsi-phy-28nm-lp";
				reg = <0x1a98300 0xd4 0x1a98500 0x280 0x1a98780 0x30>;
				reg-names = "dsi_pll", "dsi_phy", "dsi_phy_regulator";
				#clock-cells = <0x1>;
				clocks = <0x8 0x6d>;
				clock-names = "iface_clk";
				linux,phandle = <0x25>;
				phandle = <0x25>;
			};
		};
	};

	smd {
		compatible = "qcom,smd";

		rpm {
			interrupts = <0x0 0xa8 0x1>;
			qcom,ipc = <0x27 0x8 0x0>;
			qcom,smd-edge = <0xf>;

			rpm_requests {
				compatible = "qcom,rpm-msm8916";
				qcom,smd-channels = "rpm_requests";

				qcom,rpmcc {
					compatible = "qcom,rpmcc-msm8916", "qcom,rpmcc";
					#clock-cells = <0x1>;
					linux,phandle = <0x71>;
					phandle = <0x71>;
				};

				pm8916-regulators {
					compatible = "qcom,rpm-pm8916-regulators";
					linux,phandle = <0x72>;
					phandle = <0x72>;

					s1 {
						linux,phandle = <0x73>;
						phandle = <0x73>;
					};

					s3 {
						linux,phandle = <0x74>;
						phandle = <0x74>;
					};

					s4 {
						linux,phandle = <0x75>;
						phandle = <0x75>;
					};

					l1 {
						linux,phandle = <0x76>;
						phandle = <0x76>;
					};

					l2 {
						linux,phandle = <0x77>;
						phandle = <0x77>;
					};

					l3 {
						linux,phandle = <0x78>;
						phandle = <0x78>;
					};

					l4 {
						linux,phandle = <0x79>;
						phandle = <0x79>;
					};

					l5 {
						linux,phandle = <0x7a>;
						phandle = <0x7a>;
					};

					l6 {
						linux,phandle = <0x7b>;
						phandle = <0x7b>;
					};

					l7 {
						linux,phandle = <0x7c>;
						phandle = <0x7c>;
					};

					l8 {
						linux,phandle = <0x7d>;
						phandle = <0x7d>;
					};

					l9 {
						linux,phandle = <0x7e>;
						phandle = <0x7e>;
					};

					l10 {
						linux,phandle = <0x7f>;
						phandle = <0x7f>;
					};

					l11 {
						linux,phandle = <0x80>;
						phandle = <0x80>;
					};

					l12 {
						linux,phandle = <0x81>;
						phandle = <0x81>;
					};

					l13 {
						linux,phandle = <0x82>;
						phandle = <0x82>;
					};

					l14 {
						linux,phandle = <0x83>;
						phandle = <0x83>;
					};

					l15 {
						linux,phandle = <0x84>;
						phandle = <0x84>;
					};

					l16 {
						linux,phandle = <0x85>;
						phandle = <0x85>;
					};

					l17 {
						linux,phandle = <0x86>;
						phandle = <0x86>;
					};

					l18 {
						linux,phandle = <0x87>;
						phandle = <0x87>;
					};
				};
			};
		};
	};

	hexagon-smp2p {
		compatible = "qcom,smp2p";
		qcom,smem = <0x1b3 0x1ac>;
		interrupts = <0x0 0x1b 0x1>;
		qcom,ipc = <0x27 0x8 0xe>;
		qcom,local-pid = <0x0>;
		qcom,remote-pid = <0x1>;

		master-kernel {
			qcom,entry-name = "master-kernel";
			#qcom,smem-state-cells = <0x1>;
			linux,phandle = <0x88>;
			phandle = <0x88>;
		};

		slave-kernel {
			qcom,entry-name = "slave-kernel";
			interrupt-controller;
			#interrupt-cells = <0x2>;
			linux,phandle = <0x89>;
			phandle = <0x89>;
		};
	};

	wcnss-smp2p {
		compatible = "qcom,smp2p";
		qcom,smem = <0x1c3 0x1af>;
		interrupts = <0x0 0x8f 0x1>;
		qcom,ipc = <0x27 0x8 0x12>;
		qcom,local-pid = <0x0>;
		qcom,remote-pid = <0x4>;

		master-kernel {
			qcom,entry-name = "master-kernel";
			#qcom,smem-state-cells = <0x1>;
			linux,phandle = <0x8a>;
			phandle = <0x8a>;
		};

		slave-kernel {
			qcom,entry-name = "slave-kernel";
			interrupt-controller;
			#interrupt-cells = <0x2>;
			linux,phandle = <0x8b>;
			phandle = <0x8b>;
		};
	};

	smsm {
		compatible = "qcom,smsm";
		#address-cells = <0x1>;
		#size-cells = <0x0>;
		qcom,ipc-1 = <0x27 0x0 0xd>;
		qcom,ipc-6 = <0x27 0x0 0x13>;

		apps@0 {
			reg = <0x0>;
			#qcom,smem-state-cells = <0x1>;
			linux,phandle = <0x8c>;
			phandle = <0x8c>;
		};

		hexagon@1 {
			reg = <0x1>;
			interrupts = <0x0 0x1a 0x1>;
			interrupt-controller;
			#interrupt-cells = <0x2>;
			linux,phandle = <0x8d>;
			phandle = <0x8d>;
		};

		wcnss@6 {
			reg = <0x6>;
			interrupts = <0x0 0x90 0x1>;
			interrupt-controller;
			#interrupt-cells = <0x2>;
			linux,phandle = <0x8e>;
			phandle = <0x8e>;
		};
	};

	__symbols__ {
		smem_mem = "/reserved-memory/smem_region@86300000";
		mba_mem = "/reserved-memory/mba@8ea00000";
		CPU0 = "/cpus/cpu@0";
		CPU1 = "/cpus/cpu@1";
		CPU2 = "/cpus/cpu@2";
		CPU3 = "/cpus/cpu@3";
		L2_0 = "/cpus/l2-cache";
		CPU_SPC = "/cpus/idle-states/spc";
		cpu_alert0 = "/thermal-zones/cpu-thermal0/trips/trip0";
		cpu_crit0 = "/thermal-zones/cpu-thermal0/trips/trip1";
		cpu_alert1 = "/thermal-zones/cpu-thermal1/trips/trip0";
		cpu_crit1 = "/thermal-zones/cpu-thermal1/trips/trip1";
		xo_board = "/clocks/xo_board";
		sleep_clk = "/clocks/sleep_clk";
		scm = "/firmware/scm";
		soc = "/soc";
		msmgpio = "/soc/pinctrl@1000000";
		blsp1_uart1_default = "/soc/pinctrl@1000000/blsp1_uart1_default";
		blsp1_uart1_sleep = "/soc/pinctrl@1000000/blsp1_uart1_sleep";
		blsp1_uart2_default = "/soc/pinctrl@1000000/blsp1_uart2_default";
		blsp1_uart2_sleep = "/soc/pinctrl@1000000/blsp1_uart2_sleep";
		spi1_default = "/soc/pinctrl@1000000/spi1_default";
		spi1_sleep = "/soc/pinctrl@1000000/spi1_sleep";
		spi2_default = "/soc/pinctrl@1000000/spi2_default";
		spi2_sleep = "/soc/pinctrl@1000000/spi2_sleep";
		spi3_default = "/soc/pinctrl@1000000/spi3_default";
		spi3_sleep = "/soc/pinctrl@1000000/spi3_sleep";
		spi4_default = "/soc/pinctrl@1000000/spi4_default";
		spi4_sleep = "/soc/pinctrl@1000000/spi4_sleep";
		spi5_default = "/soc/pinctrl@1000000/spi5_default";
		spi5_sleep = "/soc/pinctrl@1000000/spi5_sleep";
		spi6_default = "/soc/pinctrl@1000000/spi6_default";
		spi6_sleep = "/soc/pinctrl@1000000/spi6_sleep";
		i2c2_default = "/soc/pinctrl@1000000/i2c2_default";
		i2c2_sleep = "/soc/pinctrl@1000000/i2c2_sleep";
		i2c4_default = "/soc/pinctrl@1000000/i2c4_default";
		i2c4_sleep = "/soc/pinctrl@1000000/i2c4_sleep";
		i2c6_default = "/soc/pinctrl@1000000/i2c6_default";
		i2c6_sleep = "/soc/pinctrl@1000000/i2c6_sleep";
		sdc2_cd_on = "/soc/pinctrl@1000000/sdhc2_cd_pin/cd_on";
		sdc2_cd_off = "/soc/pinctrl@1000000/sdhc2_cd_pin/cd_off";
		sdc1_clk_on = "/soc/pinctrl@1000000/pmx_sdc1_clk/clk_on";
		sdc1_clk_off = "/soc/pinctrl@1000000/pmx_sdc1_clk/clk_off";
		sdc1_cmd_on = "/soc/pinctrl@1000000/pmx_sdc1_cmd/cmd_on";
		sdc1_cmd_off = "/soc/pinctrl@1000000/pmx_sdc1_cmd/cmd_off";
		sdc1_data_on = "/soc/pinctrl@1000000/pmx_sdc1_data/data_on";
		sdc1_data_off = "/soc/pinctrl@1000000/pmx_sdc1_data/data_off";
		sdc2_clk_on = "/soc/pinctrl@1000000/pmx_sdc2_clk/clk_on";
		sdc2_clk_off = "/soc/pinctrl@1000000/pmx_sdc2_clk/clk_off";
		sdc2_cmd_on = "/soc/pinctrl@1000000/pmx_sdc2_cmd/cmd_on";
		sdc2_cmd_off = "/soc/pinctrl@1000000/pmx_sdc2_cmd/cmd_off";
		sdc2_data_on = "/soc/pinctrl@1000000/pmx_sdc2_data/data_on";
		sdc2_data_off = "/soc/pinctrl@1000000/pmx_sdc2_data/data_off";
		ext_codec_lines_act = "/soc/pinctrl@1000000/ext-codec-lines/lines_on";
		ext_codec_lines_sus = "/soc/pinctrl@1000000/ext-codec-lines/lines_off";
		cdc_pdm_lines_act = "/soc/pinctrl@1000000/cdc-pdm-lines/pdm_lines_on";
		cdc_pdm_lines_sus = "/soc/pinctrl@1000000/cdc-pdm-lines/pdm_lines_off";
		ext_pri_tlmm_lines_act = "/soc/pinctrl@1000000/ext-pri-tlmm-lines/ext_pa_on";
		ext_pri_tlmm_lines_sus = "/soc/pinctrl@1000000/ext-pri-tlmm-lines/ext_pa_off";
		ext_pri_ws_act = "/soc/pinctrl@1000000/ext-pri-ws-line/ext_pa_on";
		ext_pri_ws_sus = "/soc/pinctrl@1000000/ext-pri-ws-line/ext_pa_off";
		ext_mclk_tlmm_lines_act = "/soc/pinctrl@1000000/ext-mclk-tlmm-lines/mclk_lines_on";
		ext_mclk_tlmm_lines_sus = "/soc/pinctrl@1000000/ext-mclk-tlmm-lines/mclk_lines_off";
		ext_sec_tlmm_lines_act = "/soc/pinctrl@1000000/ext-sec-tlmm-lines/tlmm_lines_on";
		ext_sec_tlmm_lines_sus = "/soc/pinctrl@1000000/ext-sec-tlmm-lines/tlmm_lines_off";
		cdc_dmic_lines_act = "/soc/pinctrl@1000000/cdc-dmic-lines/dmic_lines_on";
		cdc_dmic_lines_sus = "/soc/pinctrl@1000000/cdc-dmic-lines/dmic_lines_off";
		cross_conn_det_act = "/soc/pinctrl@1000000/cross-conn-det/lines_on";
		cross_conn_det_sus = "/soc/pinctrl@1000000/cross-conn-det/lines_off";
		gcc = "/soc/clock-controller@1800000";
		tcsr_mutex_regs = "/soc/syscon@1905000";
		tcsr = "/soc/syscon@1937000";
		tcsr_mutex = "/soc/hwlock";
		rpm_msg_ram = "/soc/memory@60000";
		blsp1_uart1 = "/soc/serial@78af000";
		apcs = "/soc/syscon@b011000";
		blsp1_uart2 = "/soc/serial@78b0000";
		blsp_dma = "/soc/dma@7884000";
		blsp_spi1 = "/soc/spi@78b5000";
		blsp_spi2 = "/soc/spi@78b6000";
		blsp_spi3 = "/soc/spi@78b7000";
		blsp_spi4 = "/soc/spi@78b8000";
		blsp_spi5 = "/soc/spi@78b9000";
		blsp_spi6 = "/soc/spi@78ba000";
		blsp_i2c2 = "/soc/i2c@78b6000";
		blsp_i2c4 = "/soc/i2c@78b8000";
		blsp_i2c6 = "/soc/i2c@78ba000";
		lpass = "/soc/lpass@07708000";
		sdhc_1 = "/soc/sdhci@07824000";
		sdhc_2 = "/soc/sdhci@07864000";
		usb_dev = "/soc/usb@78d9000";
		usb_host = "/soc/ehci@78d9000";
		usb_otg = "/soc/phy@78d9000";
		intc = "/soc/interrupt-controller@b000000";
		spmi_bus = "/soc/spmi@200f000";
		pm8916_0 = "/soc/spmi@200f000/pm8916@0";
		pm8916_gpios = "/soc/spmi@200f000/pm8916@0/gpios@c000";
		pm8916_mpps = "/soc/spmi@200f000/pm8916@0/mpps@a000";
		pm8916_temp = "/soc/spmi@200f000/pm8916@0/temp-alarm@2400";
		pm8916_vadc = "/soc/spmi@200f000/pm8916@0/vadc@3100";
		pm8916_1 = "/soc/spmi@200f000/pm8916@1";
		qfprom = "/soc/qfprom@5c000";
		tsens_caldata = "/soc/qfprom@5c000/caldata@d0";
		tsens_calsel = "/soc/qfprom@5c000/calsel@ec";
		tsens = "/soc/thermal-sensor@4a8000";
		mdss = "/soc/mdss@1a00000";
		mdp = "/soc/mdss@1a00000/mdp@1a01000";
		mdp5_intf1_out = "/soc/mdss@1a00000/mdp@1a01000/ports/port@0/endpoint";
		dsi0 = "/soc/mdss@1a00000/dsi@1a98000";
		dsi0_in = "/soc/mdss@1a00000/dsi@1a98000/ports/port@0/endpoint";
		dsi0_out = "/soc/mdss@1a00000/dsi@1a98000/ports/port@1/endpoint";
		dsi_phy0 = "/soc/mdss@1a00000/dsi-phy@1a98300";
		rpmcc = "/smd/rpm/rpm_requests/qcom,rpmcc";
		smd_rpm_regulators = "/smd/rpm/rpm_requests/pm8916-regulators";
		pm8916_s1 = "/smd/rpm/rpm_requests/pm8916-regulators/s1";
		pm8916_s3 = "/smd/rpm/rpm_requests/pm8916-regulators/s3";
		pm8916_s4 = "/smd/rpm/rpm_requests/pm8916-regulators/s4";
		pm8916_l1 = "/smd/rpm/rpm_requests/pm8916-regulators/l1";
		pm8916_l2 = "/smd/rpm/rpm_requests/pm8916-regulators/l2";
		pm8916_l3 = "/smd/rpm/rpm_requests/pm8916-regulators/l3";
		pm8916_l4 = "/smd/rpm/rpm_requests/pm8916-regulators/l4";
		pm8916_l5 = "/smd/rpm/rpm_requests/pm8916-regulators/l5";
		pm8916_l6 = "/smd/rpm/rpm_requests/pm8916-regulators/l6";
		pm8916_l7 = "/smd/rpm/rpm_requests/pm8916-regulators/l7";
		pm8916_l8 = "/smd/rpm/rpm_requests/pm8916-regulators/l8";
		pm8916_l9 = "/smd/rpm/rpm_requests/pm8916-regulators/l9";
		pm8916_l10 = "/smd/rpm/rpm_requests/pm8916-regulators/l10";
		pm8916_l11 = "/smd/rpm/rpm_requests/pm8916-regulators/l11";
		pm8916_l12 = "/smd/rpm/rpm_requests/pm8916-regulators/l12";
		pm8916_l13 = "/smd/rpm/rpm_requests/pm8916-regulators/l13";
		pm8916_l14 = "/smd/rpm/rpm_requests/pm8916-regulators/l14";
		pm8916_l15 = "/smd/rpm/rpm_requests/pm8916-regulators/l15";
		pm8916_l16 = "/smd/rpm/rpm_requests/pm8916-regulators/l16";
		pm8916_l17 = "/smd/rpm/rpm_requests/pm8916-regulators/l17";
		pm8916_l18 = "/smd/rpm/rpm_requests/pm8916-regulators/l18";
		hexagon_smp2p_out = "/hexagon-smp2p/master-kernel";
		hexagon_smp2p_in = "/hexagon-smp2p/slave-kernel";
		wcnss_smp2p_out = "/wcnss-smp2p/master-kernel";
		wcnss_smp2p_in = "/wcnss-smp2p/slave-kernel";
		apps_smsm = "/smsm/apps@0";
		hexagon_smsm = "/smsm/hexagon@1";
		wcnss_smsm = "/smsm/wcnss@6";
	};
};
